# Qorvo_SVD register map
Vendor: Qorvo Inc; Series: ARMCM4; File version: 1.0
Registers are 8-bit, read-write, reset 0x0 unless marked. A register's access mark holds for its fields unless they carry their own. Offsets are from the block's base; [hi:lo] are bit positions.

## IR
Base 0x40001100
0x00 IR_PRESCALE_DIV reset 0x1
  [2:0] PRESCALE_DIV — Sets the divide factor for the prescaler. The prescaled frequecy is 16MHz/(2**prescale_div).
0x01 IR_THRESHOLD reset 0x1
  [7:0] THRESHOLD — Sets the 'on' time of the pwm carrier expressed in prescale clock periods. On time is: Ton = Tprescale*(threshold+1). Setting used when use_alt_carrier_configuration equals '0'.
0x02 IR_WRAP reset 0x3
  [7:0] WRAP — Sets the PWM carrier period as a function of the prescale period. Tcarrierper = Tprescale*(wrap+1). Setting used when use_alt_carrier_configuration equals '0'.
0x03 IR_ALT_THRESHOLD reset 0x1
  [7:0] ALT_THRESHOLD — Sets the 'on' time of the pwm carrier expressed in prescale clock periods. On time is: Ton = Tprescale*(threshold+1). Setting used when use_alt_carrier_configuration equals '1'.
0x04 IR_ALT_WRAP reset 0x3
  [7:0] ALT_WRAP — Sets the PWM carrier period as a function of the prescale period. Tcarrierper = Tprescale*(wrap+1). Setting used when use_alt_carrier_configuration equals '1'.
0x05 IR_CARRIER_TU reset 0x1
  [7:0] CARRIER_TU — Sets the carrier Tu in number of carrier rising edges. Is used when ir driver is in pattern mode
0x06 IR_TIMER_TU reset 0x1
  [1:0] TIMER_TU — Sets the time unit for the time based ram sequence mode. The time unit can be 500ns, 1us(=default), 2us or 4 us
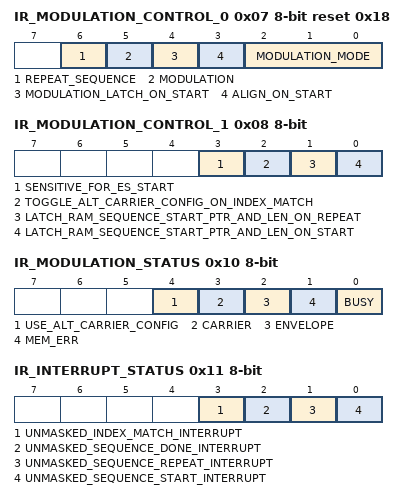
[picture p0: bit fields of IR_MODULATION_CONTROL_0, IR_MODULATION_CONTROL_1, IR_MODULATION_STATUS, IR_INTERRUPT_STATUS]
0x07 IR_MODULATION_CONTROL_0 reset 0x18
  [6] REPEAT_SEQUENCE — When set to '1', the ram sequence will be repeated when it is finished (only for time_based and pattern_based modes)
  [5] MODULATION — direct control of the modulation in the case the register_based modulation mode is chosen
  [4] MODULATION_LATCH_ON_START — When set to '1', the value of the modulation (or envelope) is sampled when the carrier period starts. In this way it can be guaranteed that carrier period is not interrupted (so no glitches)
  [3] ALIGN_ON_START — When set to '1', the carrier only starts running when the modulation is on. So the carrier is always aligned with the modulation start
  [2:0] MODULATION_MODE — Selects what source will be used for envelope modulation. Can be from registermap, from external pin, from event scheduler or from ram sequence
0x08 IR_MODULATION_CONTROL_1
  [3] SENSITIVE_FOR_ES_START — When set to '1', the ram sequencer can be start by the ES (only for time_based and pattern_based modes)
  [2] TOGGLE_ALT_CARRIER_CONFIG_ON_INDEX_MATCH — When set to '1', the use_alt_carrier_config will be toggle on an index match (only for time_based and pattern_based modes)
  [1] LATCH_RAM_SEQUENCE_START_PTR_AND_LEN_ON_REPEAT — When set to '1', the ram sequence start pointer and ram sequence length are latched when a ram sequence is repeated, because the repeat seuance bit was set (only for time_based and pattern_based modes)
  [0] LATCH_RAM_SEQUENCE_START_PTR_AND_LEN_ON_START — When set to '1', the ram sequence start pointer and ram sequence length are latched when a ram sequence is fired (only for time_based and pattern_based modes)
0x0A IR_RAM_SEQUENCE_START_PTR 16-bit
  [15:0] RAM_SEQUENCE_START_PTR — Sets the start pointer of the ram modulation sequence block (16 bit word address offset with respect to RAM start adddress)
0x0C IR_RAM_SEQUENCE_LEN
  [7:0] RAM_SEQUENCE_LEN — Sets the length of the ram sequence - len is set to number of entries - 1
0x0D IR_RAM_SEQUENCE_MATCH_INDEX
  [7:0] RAM_SEQUENCE_MATCH_INDEX — Sets the index value that is checked for matches
0x10 IR_MODULATION_STATUS ro
  [4] USE_ALT_CARRIER_CONFIG — when '0', threshold and wrap are used for carrier generation. when '1', alt_threshold and alt_wrap are used for carrier generation.
  [3] CARRIER — Shows the status of the carrier - just for observability
  [2] ENVELOPE — Shows the status of the envelope - just for observability
  [1] MEM_ERR — indicates that the ram sequence was aborted because of a memory access err-or
  [0] BUSY — ram sequence is ongoing
0x11 IR_INTERRUPT_STATUS ro
  [3] UNMASKED_INDEX_MATCH_INTERRUPT — unmasked interrupt status of the interrupt triggered by the ram sequence hitting a certain index
  [2] UNMASKED_SEQUENCE_DONE_INTERRUPT — unmasked interrupt status of the interrupt triggered by finishing a ram sequence
  [1] UNMASKED_SEQUENCE_REPEAT_INTERRUPT — unmasked interrupt status of the interrupt triggered by repeating a ram sequence
  [0] UNMASKED_SEQUENCE_START_INTERRUPT — unmasked interrupt status of the interrupt triggered by starting a ram sequence
0x12 IR_SEQUENCE_IDX ro
  [7:0] SEQUENCE_IDX — shows the what index in the ram sequence is currently being executed
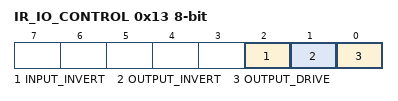
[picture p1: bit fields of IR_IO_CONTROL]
0x13 IR_IO_CONTROL
  [2] INPUT_INVERT — inverts the input
  [1] OUTPUT_INVERT — Inverts the output
  [0] OUTPUT_DRIVE — Sets the drive type for the output
